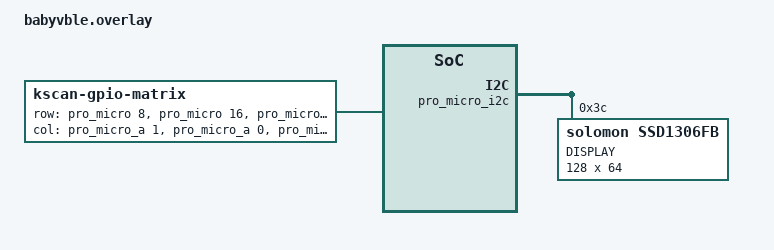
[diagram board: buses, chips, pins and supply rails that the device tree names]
/*
 * Copyright (c) 2021 Pete Johanson, Richard Jones
 *
 * SPDX-License-Identifier: MIT
 */

#include <dt-bindings/zmk/matrix_transform.h>

/ {
	chosen {
		zmk,kscan = &kscan0;
	};

	kscan0: kscan {
		compatible = "zmk,kscan-gpio-matrix";
		label = "KSCAN";

		diode-direction = "col2row";
		row-gpios
			= <&pro_micro 8 (GPIO_ACTIVE_HIGH | GPIO_PULL_DOWN)>
			, <&pro_micro 16 (GPIO_ACTIVE_HIGH | GPIO_PULL_DOWN)>
			, <&pro_micro 9 (GPIO_ACTIVE_HIGH | GPIO_PULL_DOWN)>
			, <&pro_micro 10 (GPIO_ACTIVE_HIGH | GPIO_PULL_DOWN)>
			;

		col-gpios
			= <&pro_micro_a  1 GPIO_ACTIVE_HIGH>
			, <&pro_micro_a  0 GPIO_ACTIVE_HIGH>
			, <&pro_micro_d  4 GPIO_ACTIVE_HIGH>
			, <&pro_micro_d  5 GPIO_ACTIVE_HIGH>
			, <&pro_micro_d  6 GPIO_ACTIVE_HIGH>
			, <&pro_micro_d  7 GPIO_ACTIVE_HIGH>
			, <&pro_micro_d  14 GPIO_ACTIVE_HIGH>
			, <&pro_micro_d  15 GPIO_ACTIVE_HIGH>
			, <&pro_micro_d  18 GPIO_ACTIVE_HIGH>
			, <&pro_micro_d  19 GPIO_ACTIVE_HIGH>
			, <&pro_micro_d  20 GPIO_ACTIVE_HIGH>
			, <&pro_micro_d  21 GPIO_ACTIVE_HIGH>
			;
	};
};

&pro_micro_i2c {
	status = "okay";

	ssd1306@3c {
		compatible = "solomon,ssd1306fb";
		reg = <0x3c>;
		label = "DISPLAY";
		width = <128>;
		height = <64>;
		segment-offset = <0>;
		page-offset = <0>;
		display-offset = <0>;
		multiplex-ratio = <63>;
		prechargep = <0x22>;
	};
};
